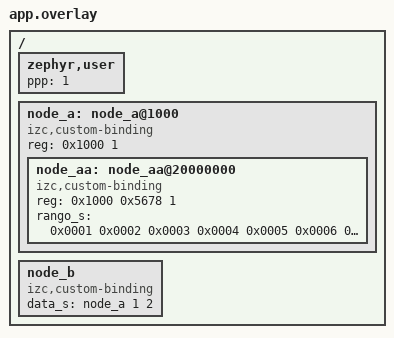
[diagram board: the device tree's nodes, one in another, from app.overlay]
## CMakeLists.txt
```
# SPDX-License-Identifier: Apache-2.0

cmake_minimum_required(VERSION 3.20.0)
find_package(Zephyr REQUIRED HINTS $ENV{ZEPHYR_BASE})
project(blinky)

add_subdirectory(src/util)

target_sources(app PRIVATE src/util/util.c)
target_sources(app PRIVATE src/main.cpp)

target_link_libraries(app PRIVATE newlib)
```

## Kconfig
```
menu "iomico options"

config IOMICO_OPTION_A
    bool "IOMICO option A"
    default n

config IOMICO_OPTION_B
    int "iomico option B"
    default 10

rsource "services/Kconfig.services"


endmenu

menu "zephyr options"

source "Kconfig.zephyr"

endmenu
```

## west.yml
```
manifest:
  defaults:
    remote: upstream

  remotes:
    - name: upstream
      url-base: https://github.com/zephyrproject-rtos

  self:
    path: iomico_blinky
  #
  # Please add items below based on alphabetical order
  projects:
    - name: zephyr
      remote: upstream
      #revision: main
      revision: v3.6.0
      import:
        # By using name-allowlist we can clone only the modules that are
        # strictly needed by the application.
        name-allowlist:
          - cmsis      # required by the ARM port
          - hal_nordic # required by the custom_plank board (Nordic based)

        #if not using name-allowlist, the following is an example of how to
        #specify the modules to be imported one by one
          #  projects:
          #        - name: cmsis
          #        #if not specified, the default remote is used
          #          remote: upstream
          #          revision: 4b96cbb174678dcd3ca86e11e1f24bc5f8726da0
          #          path: modules/hal/cmsis
          #          groups:
          #            - hal
```

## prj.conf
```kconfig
CONFIG_CPP=y
CONFIG_STD_CPP17=y

CONFIG_NEWLIB_LIBC=y
CONFIG_NEWLIB_LIBC_NANO=y

CONFIG_PRINTK=y
CONFIG_HEAP_MEM_POOL_SIZE=4096
CONFIG_ASSERT=y
CONFIG_GPIO=y

# Enable logging
CONFIG_LOG=y

# Set default log level
CONFIG_LOG_DEFAULT_LEVEL=3
```

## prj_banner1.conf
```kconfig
CONFIG_PRINTK=y
CONFIG_HEAP_MEM_POOL_SIZE=256
CONFIG_ASSERT=y
CONFIG_GPIO=y

# Enable logging
CONFIG_LOG=y

# Set default log level
CONFIG_LOG_DEFAULT_LEVEL=3
```

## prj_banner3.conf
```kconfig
CONFIG_SYS_CLOCK_HW_CYCLES_PER_SEC=1000000
CONFIG_GPIO=y
CONFIG_LOG=y
CONFIG_ASSERT=y
CONFIG_CONSOLE=y
CONFIG_BOOT_BANNER_STRING="BANNER3"
CONFIG_HEAP_MEM_POOL_SIZE=256
```

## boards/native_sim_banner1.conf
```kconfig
CONFIG_BOOT_DELAY=1111
```

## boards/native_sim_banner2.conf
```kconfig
CONFIG_BOOT_DELAY=2222
```

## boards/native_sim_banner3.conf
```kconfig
CONFIG_SYS_CLOCK_HW_CYCLES_PER_SEC=1000000
CONFIG_GPIO=y
CONFIG_LOG=y
CONFIG_ASSERT=y
CONFIG_CONSOLE=y
CONFIG_BOOT_BANNER_STRING="banner1"
CONFIG_BOOT_DELAY=1111
CONFIG_HEAP_MEM_POOL_SIZE=256
```

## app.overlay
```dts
/ { 
   #address-cells = <1>;
   #size-cells = <1>;

   zephyr,user {
   //   data_s = <&node_a 22 44>;
      ppp = <1>;
   };

   node_a: node_a@1000 {
      compatible = "izc,custom-binding";
      #address-cells = <2>;
      #size-cells = <1>;

      //data_-cells is a custom proprerty declared in custom-binding.yml
      #data_-cells = <2>;

      reg = <0x1000 1>;
      node_aa: node_aa@20000000 {
         compatible = "izc,custom-binding";
         #address-cells = <2>;
         #size-cells = <1>;
         reg = <0x1000 0x5678 1>;

         //rango_s is a custom proprerty declared in custom-binding.yml
         rango_s = <0x0001 0x0002 0x0003 0x0004 0x0005 0x0006 0x0007 0x0008 0x0009 0x000A>;
      };
   };

   node_b: node_b {
      compatible = "izc,custom-binding";
      // &node_a phandle
      // 1 2 are specifiers
      data_s = <&node_a 1 2>;
   };
};
```

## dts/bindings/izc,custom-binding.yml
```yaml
description: "custom device tree binding for iomico zephyr course"

compatible: "izc,custom-binding"

include: [base.yaml]

properties:
  #this is a custom property for iomico zephyr course and must end in 's'...
  #yep.. it must end in 's' as I tould you before
  rango_s:
    type: array
    description: "array custom property for iomico zephyr course"
    required: false


  #this is a custom property for iomico zephyr course and must end in 's'...
  #yep.. it must end in 's' as I tould you before
  data_s:
    type: phandle-array
    description: "phandle-array custom property for iomico zephyr course"
    required: false

  "#data-cells":
    type: int
    required: false
    description: "int custom property for iomico zephyr course"

data_-cells:
  - data1
  - data2
```

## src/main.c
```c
#include <stdio.h>
#include <zephyr/logging/log.h>

//LOG_MODULE_REGISTER(my_module, LOG_LEVEL_DBG);
LOG_MODULE_REGISTER(my_module2, LOG_LEVEL_DBG);

int main() 
{
   LOG_INF("hola");
   LOG_ERR("hola");
   printf("Hello, World!\n");
// printf("Hello, World! %u %u\n",CONFIG_IOMICO_OPTION_A,CONFIG_IOMICO_OPTION_B);

 return 0;
}
```

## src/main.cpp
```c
#include <stdio.h>
#include <zephyr/logging/log.h>

#define MAX_BOARD_NAME_LEN 20

class myConfigClass {
   public:
      bool cppEnable;
      bool cpp17;
      char boardName[MAX_BOARD_NAME_LEN];
} myConfig;

int main(void) 
{
   myConfig.cppEnable = CONFIG_CPP;
   myConfig.cpp17     = CONFIG_STD_CPP17;
   strncpy(myConfig.boardName, CONFIG_BOARD, MAX_BOARD_NAME_LEN);
   printf("board name: %s is cpp enable? %u version 17? %u\r\n",myConfig.boardName,myConfig.cppEnable,myConfig.cpp17);

   return 0;
}
```

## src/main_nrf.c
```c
/*
 * Copyright (c) 2016 Intel Corporation
 *
 * SPDX-License-Identifier: Apache-2.0
 */

#include <stdio.h>
#include <zephyr/kernel.h>
#include <zephyr/drivers/gpio.h>
#include <zephyr/device.h>
#include <zephyr/drivers/gpio.h>
#include <zephyr/sys/printk.h>
#include <zephyr/sys/__assert.h>
#include <string.h>
#include <zephyr/sys/util.h>
#include <inttypes.h>

/* 1000 msec = 1 sec */
#define SLEEP_TIME_MS   200

/* size of stack area used by each thread */
#define STACKSIZE 1024

/* scheduling priority used by each thread */
#define PRIORITY 7

/* The devicetree node identifier for the "led0" alias. */
#define LED0_NODE DT_ALIAS(led0)
#define LED1_NODE DT_ALIAS(led1)

/*
 * A build error on this line means your board is unsupported.
 * See the sample documentation for information on how to fix this.
 */
static const struct gpio_dt_spec led = GPIO_DT_SPEC_GET(LED0_NODE, gpios);

/*
 * Get button configuration from the devicetree sw0 alias. This is mandatory.
 */
#define SW0_NODE	DT_ALIAS(sw0)
#if !DT_NODE_HAS_STATUS_OKAY(SW0_NODE)
#error "Unsupported board: sw0 devicetree alias is not defined"
#endif
static const struct gpio_dt_spec button = GPIO_DT_SPEC_GET_OR(SW0_NODE, gpios, {0});
static struct gpio_callback button_cb_data;

struct printk_data_t {
	void *fifo_reserved; /* 1st word reserved for use by fifo */
	uint32_t led;
	uint32_t cnt;
};

K_FIFO_DEFINE(printk_fifo);

struct led {
	struct gpio_dt_spec spec;
	uint8_t num;
};

static const struct led led0 = {
	.spec = GPIO_DT_SPEC_GET_OR(LED0_NODE, gpios, {0}),
	.num = 0,
};

static const struct led led1 = {
	.spec = GPIO_DT_SPEC_GET_OR(LED1_NODE, gpios, {0}),
	.num = 1,
};

void blink(const struct led *led, uint32_t sleep_ms, uint32_t id)
{
	const struct gpio_dt_spec *spec = &led->spec;
	int cnt = 0;
	int ret;

	if (!device_is_ready(spec->port)) {
		printk("Error: %s device is not ready\n", spec->port->name);
		return;
	}

	ret = gpio_pin_configure_dt(spec, GPIO_OUTPUT);
	if (ret != 0) {
		printk("Error %d: failed to configure pin %d (LED '%d')\n",
			ret, spec->pin, led->num);
		return;
	}

	while (1) {
		gpio_pin_set(spec->port, spec->pin, cnt % 2);

		struct printk_data_t tx_data = { .led = id, .cnt = cnt };

		size_t size = sizeof(struct printk_data_t);
		char *mem_ptr = k_malloc(size);
		__ASSERT_NO_MSG(mem_ptr != 0);

		memcpy(mem_ptr, &tx_data, size);

		k_fifo_put(&printk_fifo, mem_ptr);

		k_msleep(sleep_ms);
		cnt++;
	}
}

void blink0(void)
{
	blink(&led0, 100, 0);
}

void blink1(void)
{
	blink(&led1, 1000, 1);
}

void uart_out(void)
{
	while (1) {
		struct printk_data_t *rx_data = k_fifo_get(&printk_fifo,
							   K_FOREVER);
		printk("Toggled led%d; counter=%d\n",
		       rx_data->led, rx_data->cnt);
		k_free(rx_data);
	}
}

K_THREAD_DEFINE(blink0_id, STACKSIZE, blink0, NULL, NULL, NULL,
		PRIORITY, 0, 0);
K_THREAD_DEFINE(blink1_id, STACKSIZE, blink1, NULL, NULL, NULL,
		PRIORITY, 0, 0);
K_THREAD_DEFINE(uart_out_id, STACKSIZE, uart_out, NULL, NULL, NULL,
		PRIORITY, 0, 0);


void button_pressed(const struct device *dev, struct gpio_callback *cb, uint32_t pins)
{
	printk("Button pressed at %" PRIu32 "\n", k_cycle_get_32());
}

int btn(void)
{
	int ret;

	if (!gpio_is_ready_dt(&button)) {
		printk("Error: button device %s is not ready\n",
		       button.port->name);
		return 0;
	}

	ret = gpio_pin_configure_dt(&button, GPIO_INPUT);
	if (ret != 0) {
		printk("Error %d: failed to configure %s pin %d\n",
		       ret, button.port->name, button.pin);
		return 0;
	}

	ret = gpio_pin_interrupt_configure_dt(&button, GPIO_INT_EDGE_TO_ACTIVE);
	if (ret != 0) {
		printk("Error %d: failed to configure interrupt on %s pin %d\n",
			ret, button.port->name, button.pin);
		return 0;
	}

	gpio_init_callback(&button_cb_data, button_pressed, BIT(button.pin));
	gpio_add_callback(button.port, &button_cb_data);
	printk("Set up button at %s pin %d\n", button.port->name, button.pin);

	printk("Press the button\n");
    while (1) {
       int val = gpio_pin_get_dt(&button);

       if (val > 0) {
          printk("btn pressed val: %u\n", val);
       }
       k_msleep(SLEEP_TIME_MS);
    }
	return 0;
}

K_THREAD_DEFINE(btn_id, STACKSIZE, btn, NULL, NULL, NULL, PRIORITY, 0, 0);
```
